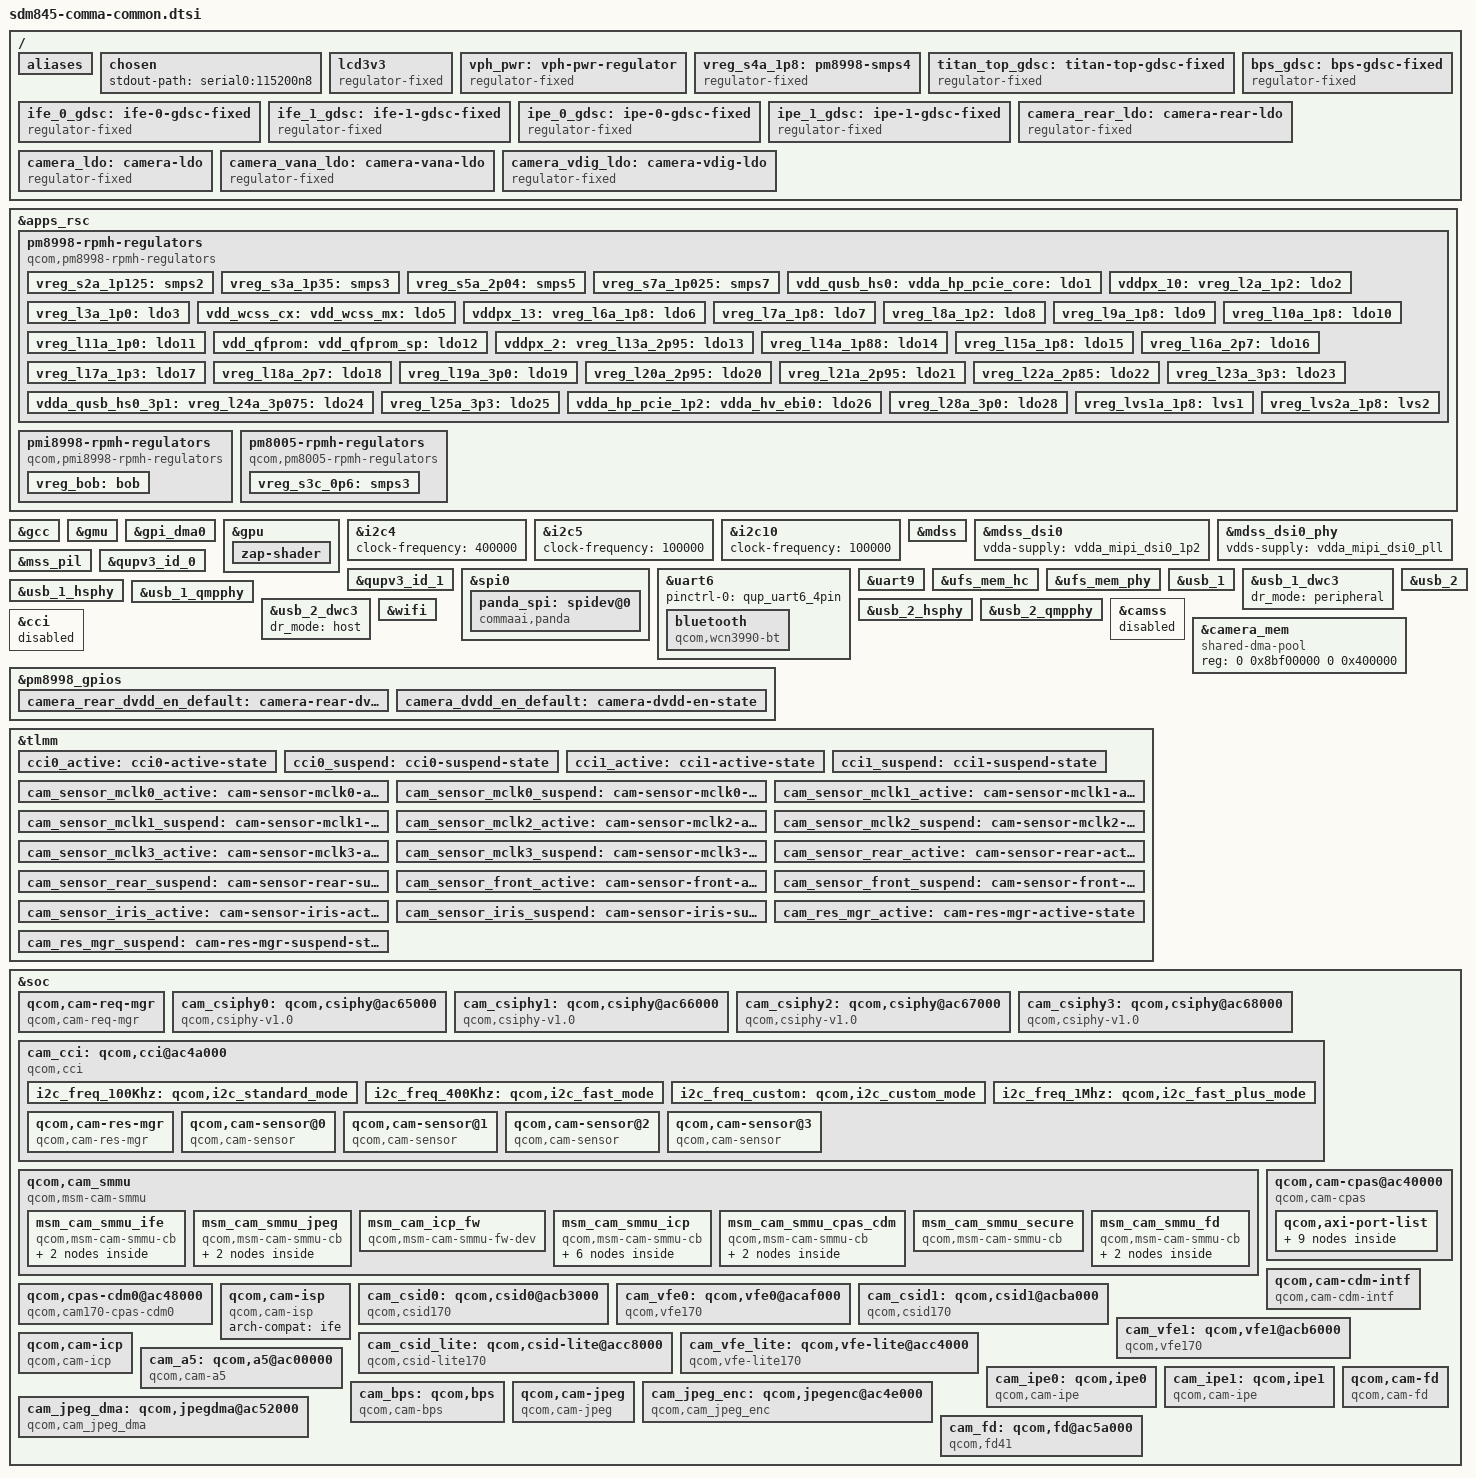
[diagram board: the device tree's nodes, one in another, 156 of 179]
/dts-v1/;

#include <dt-bindings/regulator/qcom,rpmh-regulator.h>
#include <dt-bindings/pinctrl/qcom,pmic-gpio.h>
#include "sdm845.dtsi"
#include "pm8998.dtsi"
#include "pmi8998.dtsi"

/ {
	aliases {
		serial0 = &uart9;

		/*
		 * openpilot opens fixed i2c bus numbers: IMU on bus 1
		 * (sensord.py I2C_BUS_IMU=1), ina231 power monitor on bus 0,
		 * touch on bus 2. Linux derives the adapter number from these
		 * aliases (of_alias_get_id). Upstream sdm845.dtsi ships identity
		 * aliases (i2cN=&i2cN), so without this override the IMU node
		 * (i2c@890000 = i2c4) would be bus 4. Remap the three buses we
		 * use to the legacy numbers and park the displaced identity
		 * aliases on unused nodes so no two aliases target one node.
		 *
		 * Matches agnos legacy DTS: se10=/dev/i2c-0 (power),
		 * se4=IMU bus 1, se5=/dev/i2c-2 (touch).
		 */
		i2c0 = &i2c10;	/* i2c@a88000  legacy /dev/i2c-0 (no devices on mici) */
		i2c1 = &i2c4;	/* i2c@890000  IMU            */
		i2c2 = &i2c5;	/* i2c@894000  touch          */
		i2c4 = &i2c0;
		i2c5 = &i2c1;
		i2c10 = &i2c2;
	};

	chosen {
		stdout-path = "serial0:115200n8";
	};

	lcd3v3: lcd3v3 {
		compatible = "regulator-fixed";
		regulator-name = "lcd3v3";
		regulator-min-microvolt = <3300000>;
		regulator-max-microvolt = <3300000>;
		gpio = <&pm8998_gpios 13 0>;
		regulator-boot-on;
	};

	vph_pwr: vph-pwr-regulator {
		compatible = "regulator-fixed";
		regulator-name = "vph_pwr";
		regulator-min-microvolt = <3700000>;
		regulator-max-microvolt = <3700000>;
	};

	/*
	 * Apparently RPMh does not provide support for PM8998 S4 because it
	 * is always-on; model it as a fixed regulator.
	 */
	vreg_s4a_1p8: pm8998-smps4 {
		compatible = "regulator-fixed";
		regulator-name = "vreg_s4a_1p8";

		regulator-min-microvolt = <1800000>;
		regulator-max-microvolt = <1800000>;

		regulator-always-on;
		regulator-boot-on;

		vin-supply = <&vph_pwr>;
	};

	/*
	 * Camera GDSC stand-in regulators (Spectra port).
	 *
	 * The downstream Spectra camera driver (cam_soc_util.c) acquires its
	 * power domains via the *regulator* framework: regulator_get(dev,
	 * "camss-vdd"/"gdscr"/"ife0"/...) — it has no genpd/pm_runtime path.
	 * On the legacy 4.9 tree titan_top_gdsc / ife_*_gdsc / ipe_*_gdsc /
	 * bps_gdsc were "qcom,gdsc" regulators poking individual registers in
	 * the camcc block. In mainline 6.18 those same registers belong to the
	 * &clock_camcc clock-controller, which exposes them as genpd
	 * power-domains (#power-domain-cells=1, TITAN_TOP_GDSC etc.) — there is
	 * no standalone gdsc regulator to point at. So provide always-on fixed
	 * regulators with the legacy labels to satisfy the driver's
	 * regulator_get() calls; the genuine HW power-gating is handled by the
	 * camcc genpd (the cam-cpas node additionally attaches TITAN_TOP_GDSC
	 * as a power-domain so the Titan top rail is actually enabled — see
	 * &soc cam-cpas below). always-on/boot-on keeps the bring-up faithful.
	 */
	titan_top_gdsc: titan-top-gdsc-fixed {
		compatible = "regulator-fixed";
		regulator-name = "titan_top_gdsc";
		regulator-always-on;
		regulator-boot-on;
	};

	ife_0_gdsc: ife-0-gdsc-fixed {
		compatible = "regulator-fixed";
		regulator-name = "ife_0_gdsc";
		regulator-always-on;
		regulator-boot-on;
	};

	ife_1_gdsc: ife-1-gdsc-fixed {
		compatible = "regulator-fixed";
		regulator-name = "ife_1_gdsc";
		regulator-always-on;
		regulator-boot-on;
	};

	ipe_0_gdsc: ipe-0-gdsc-fixed {
		compatible = "regulator-fixed";
		regulator-name = "ipe_0_gdsc";
		regulator-always-on;
		regulator-boot-on;
	};

	ipe_1_gdsc: ipe-1-gdsc-fixed {
		compatible = "regulator-fixed";
		regulator-name = "ipe_1_gdsc";
		regulator-always-on;
		regulator-boot-on;
	};

	bps_gdsc: bps-gdsc-fixed {
		compatible = "regulator-fixed";
		regulator-name = "bps_gdsc";
		regulator-always-on;
		regulator-boot-on;
	};

	/*
	 * Per-sensor digital/analog LDOs (Spectra port). Legacy
	 * sdm845-camera-sensor-mtp.dtsi modeled these as GPIO-gated
	 * regulator-fixed nodes (camera_rear_ldo / camera_ldo on pm8998 GPIOs
	 * 12/9; camera_vana_ldo / camera_vdig_ldo as always-on fixed). Kept
	 * identical here so the cam-sensor nodes' cam_vdig/cam_vana supplies
	 * resolve to the same rails as the working legacy DTS.
	 */
	/*
	 * cam_vdig (1.05 V) stand-ins, GPIO-enabled via pm8998 gpio12 (sensors
	 * 0-2) / gpio9 (sensor 3). Follows the mainline db845c cam0_dvdd_1v2
	 * pattern exactly: regulator-fixed + enable-active-high gpiod + a
	 * pinctrl-0 that muxes the pm8998 pin to a push-pull, high-strength
	 * output (the SPMI GPIO output buffer is open-drain/weak by default, so
	 * without drive-push-pull a gpiod output-high reads back low / high-Z and
	 * never sources the LDO enable — that was the CCI chip-id NACK). The
	 * device core applies pinctrl-0 (PINCTRL_STATE_DEFAULT) before probe, so
	 * the function/drive config lands before fixed.c requests the gpiod.
	 */
	camera_rear_ldo: camera-rear-ldo {
		compatible = "regulator-fixed";
		regulator-name = "camera_rear_ldo";
		regulator-min-microvolt = <1050000>;
		regulator-max-microvolt = <1050000>;
		gpio = <&pm8998_gpios 12 GPIO_ACTIVE_HIGH>;
		enable-active-high;
		pinctrl-names = "default";
		pinctrl-0 = <&camera_rear_dvdd_en_default>;
		regulator-always-on;
		regulator-boot-on;
	};

	camera_ldo: camera-ldo {
		compatible = "regulator-fixed";
		regulator-name = "camera_ldo";
		regulator-min-microvolt = <1050000>;
		regulator-max-microvolt = <1050000>;
		gpio = <&pm8998_gpios 9 GPIO_ACTIVE_HIGH>;
		enable-active-high;
		pinctrl-names = "default";
		pinctrl-0 = <&camera_dvdd_en_default>;
		regulator-always-on;
		regulator-boot-on;
	};

	camera_vana_ldo: camera-vana-ldo {
		compatible = "regulator-fixed";
		regulator-name = "camera_vana_ldo";
		regulator-min-microvolt = <2850000>;
		regulator-max-microvolt = <2850000>;
		regulator-enable-ramp-delay = <233>;
		enable-active-high;
	};

	camera_vdig_ldo: camera-vdig-ldo {
		compatible = "regulator-fixed";
		regulator-name = "camera_vdig_ldo";
		regulator-min-microvolt = <1050000>;
		regulator-max-microvolt = <1050000>;
		regulator-enable-ramp-delay = <233>;
		enable-active-high;
	};
};

&apps_rsc {
	pm8998-rpmh-regulators {
		compatible = "qcom,pm8998-rpmh-regulators";
		qcom,pmic-id = "a";

		vdd-s1-supply = <&vph_pwr>;
		vdd-s2-supply = <&vph_pwr>;
		vdd-s3-supply = <&vph_pwr>;
		vdd-s4-supply = <&vph_pwr>;
		vdd-s5-supply = <&vph_pwr>;
		vdd-s6-supply = <&vph_pwr>;
		vdd-s7-supply = <&vph_pwr>;
		vdd-s8-supply = <&vph_pwr>;
		vdd-s9-supply = <&vph_pwr>;
		vdd-s10-supply = <&vph_pwr>;
		vdd-s11-supply = <&vph_pwr>;
		vdd-s12-supply = <&vph_pwr>;
		vdd-s13-supply = <&vph_pwr>;
		vdd-l1-l27-supply = <&vreg_s7a_1p025>;
		vdd-l2-l8-l17-supply = <&vreg_s3a_1p35>;
		vdd-l3-l11-supply = <&vreg_s7a_1p025>;
		vdd-l4-l5-supply = <&vreg_s7a_1p025>;
		vdd-l6-supply = <&vph_pwr>;
		vdd-l7-l12-l14-l15-supply = <&vreg_s5a_2p04>;
		vdd-l9-supply = <&vreg_bob>;
		vdd-l10-l23-l25-supply = <&vreg_bob>;
		vdd-l13-l19-l21-supply = <&vreg_bob>;
		vdd-l16-l28-supply = <&vreg_bob>;
		vdd-l18-l22-supply = <&vreg_bob>;
		vdd-l20-l24-supply = <&vreg_bob>;
		vdd-l26-supply = <&vreg_s3a_1p35>;
		vin-lvs-1-2-supply = <&vreg_s4a_1p8>;

		vreg_s2a_1p125: smps2 {
			regulator-min-microvolt = <1100000>;
			regulator-max-microvolt = <1100000>;
		};

		vreg_s3a_1p35: smps3 {
			regulator-min-microvolt = <1352000>;
			regulator-max-microvolt = <1352000>;
		};

		vreg_s5a_2p04: smps5 {
			regulator-min-microvolt = <1904000>;
			regulator-max-microvolt = <2040000>;
		};

		vreg_s7a_1p025: smps7 {
			regulator-min-microvolt = <900000>;
			regulator-max-microvolt = <1028000>;
		};

		vdd_qusb_hs0:
		vdda_hp_pcie_core:
		vdda_mipi_csi0_0p9:
		vdda_mipi_csi1_0p9:
		vdda_mipi_csi2_0p9:
		vdda_mipi_dsi0_pll:
		vdda_mipi_dsi1_pll:
		vdda_qlink_lv:
		vdda_qlink_lv_ck:
		vdda_qrefs_0p875:
		vdda_pcie_core:
		vdda_pll_cc_ebi01:
		vdda_pll_cc_ebi23:
		vdda_sp_sensor:
		vdda_ufs1_core:
		vdda_ufs2_core:
		vdda_usb1_ss_core:
		vdda_usb2_ss_core:
		vreg_l1a_0p875: ldo1 {
			regulator-min-microvolt = <880000>;
			regulator-max-microvolt = <880000>;
			regulator-initial-mode = <RPMH_REGULATOR_MODE_HPM>;
		};

		vddpx_10:
		vreg_l2a_1p2: ldo2 {
			regulator-min-microvolt = <1200000>;
			regulator-max-microvolt = <1200000>;
			regulator-initial-mode = <RPMH_REGULATOR_MODE_HPM>;
			regulator-always-on;
		};

		vreg_l3a_1p0: ldo3 {
			regulator-min-microvolt = <1000000>;
			regulator-max-microvolt = <1000000>;
			regulator-initial-mode = <RPMH_REGULATOR_MODE_HPM>;
		};

		vdd_wcss_cx:
		vdd_wcss_mx:
		vdda_wcss_pll:
		vreg_l5a_0p8: ldo5 {
			regulator-min-microvolt = <800000>;
			regulator-max-microvolt = <800000>;
			regulator-initial-mode = <RPMH_REGULATOR_MODE_HPM>;
		};

		vddpx_13:
		vreg_l6a_1p8: ldo6 {
			regulator-min-microvolt = <1856000>;
			regulator-max-microvolt = <1856000>;
			regulator-initial-mode = <RPMH_REGULATOR_MODE_HPM>;
		};

		vreg_l7a_1p8: ldo7 {
			regulator-min-microvolt = <1800000>;
			regulator-max-microvolt = <1800000>;
			regulator-initial-mode = <RPMH_REGULATOR_MODE_HPM>;
		};

		vreg_l8a_1p2: ldo8 {
			regulator-min-microvolt = <1200000>;
			regulator-max-microvolt = <1248000>;
			regulator-initial-mode = <RPMH_REGULATOR_MODE_HPM>;
		};

		vreg_l9a_1p8: ldo9 {
			regulator-min-microvolt = <1704000>;
			regulator-max-microvolt = <2928000>;
			regulator-initial-mode = <RPMH_REGULATOR_MODE_HPM>;
		};

		vreg_l10a_1p8: ldo10 {
			regulator-min-microvolt = <1704000>;
			regulator-max-microvolt = <2928000>;
			regulator-initial-mode = <RPMH_REGULATOR_MODE_HPM>;
		};

		vreg_l11a_1p0: ldo11 {
			regulator-min-microvolt = <1000000>;
			regulator-max-microvolt = <1048000>;
			regulator-initial-mode = <RPMH_REGULATOR_MODE_HPM>;
		};

		vdd_qfprom:
		vdd_qfprom_sp:
		vdda_apc1_cs_1p8:
		vdda_gfx_cs_1p8:
		vdda_qrefs_1p8:
		vdda_qusb_hs0_1p8:
		vddpx_11:
		vreg_l12a_1p8: ldo12 {
			regulator-min-microvolt = <1800000>;
			regulator-max-microvolt = <1800000>;
			regulator-initial-mode = <RPMH_REGULATOR_MODE_HPM>;
		};

		vddpx_2:
		vreg_l13a_2p95: ldo13 {
			regulator-min-microvolt = <1800000>;
			regulator-max-microvolt = <2960000>;
			regulator-initial-mode = <RPMH_REGULATOR_MODE_HPM>;
		};

		vreg_l14a_1p88: ldo14 {
			regulator-min-microvolt = <1800000>;
			regulator-max-microvolt = <1800000>;
			regulator-initial-mode = <RPMH_REGULATOR_MODE_HPM>;
		};

		vreg_l15a_1p8: ldo15 {
			regulator-min-microvolt = <1800000>;
			regulator-max-microvolt = <1800000>;
			regulator-initial-mode = <RPMH_REGULATOR_MODE_HPM>;
		};

		vreg_l16a_2p7: ldo16 {
			regulator-min-microvolt = <2704000>;
			regulator-max-microvolt = <2704000>;
			regulator-initial-mode = <RPMH_REGULATOR_MODE_HPM>;
		};

		vreg_l17a_1p3: ldo17 {
			regulator-min-microvolt = <1304000>;
			regulator-max-microvolt = <1304000>;
			regulator-initial-mode = <RPMH_REGULATOR_MODE_HPM>;
		};

		vreg_l18a_2p7: ldo18 {
			regulator-min-microvolt = <2704000>;
			regulator-max-microvolt = <2960000>;
			regulator-initial-mode = <RPMH_REGULATOR_MODE_HPM>;
		};

		vreg_l19a_3p0: ldo19 {
			regulator-min-microvolt = <2856000>;
			regulator-max-microvolt = <3104000>;
			regulator-initial-mode = <RPMH_REGULATOR_MODE_HPM>;
		};

		vreg_l20a_2p95: ldo20 {
			regulator-min-microvolt = <2704000>;
			regulator-max-microvolt = <2960000>;
			regulator-initial-mode = <RPMH_REGULATOR_MODE_HPM>;
		};

		vreg_l21a_2p95: ldo21 {
			regulator-min-microvolt = <2704000>;
			regulator-max-microvolt = <2960000>;
			regulator-initial-mode = <RPMH_REGULATOR_MODE_HPM>;
		};

		vreg_l22a_2p85: ldo22 {
			regulator-min-microvolt = <2864000>;
			regulator-max-microvolt = <3312000>;
			regulator-initial-mode = <RPMH_REGULATOR_MODE_HPM>;
		};

		vreg_l23a_3p3: ldo23 {
			regulator-min-microvolt = <3000000>;
			regulator-max-microvolt = <3312000>;
			regulator-initial-mode = <RPMH_REGULATOR_MODE_HPM>;
		};

		vdda_qusb_hs0_3p1:
		vreg_l24a_3p075: ldo24 {
			regulator-min-microvolt = <3088000>;
			regulator-max-microvolt = <3088000>;
			regulator-initial-mode = <RPMH_REGULATOR_MODE_HPM>;
		};

		vreg_l25a_3p3: ldo25 {
			regulator-min-microvolt = <3300000>;
			regulator-max-microvolt = <3312000>;
			regulator-initial-mode = <RPMH_REGULATOR_MODE_HPM>;
		};

		vdda_hp_pcie_1p2:
		vdda_hv_ebi0:
		vdda_hv_ebi1:
		vdda_hv_ebi2:
		vdda_hv_ebi3:
		vdda_mipi_csi_1p25:
		vdda_mipi_dsi0_1p2:
		vdda_mipi_dsi1_1p2:
		vdda_pcie_1p2:
		vdda_ufs1_1p2:
		vdda_ufs2_1p2:
		vdda_usb1_ss_1p2:
		vdda_usb2_ss_1p2:
		vreg_l26a_1p2: ldo26 {
			regulator-min-microvolt = <1200000>;
			regulator-max-microvolt = <1200000>;
			regulator-initial-mode = <RPMH_REGULATOR_MODE_HPM>;
		};

		vreg_l28a_3p0: ldo28 {
			regulator-min-microvolt = <2856000>;
			regulator-max-microvolt = <3008000>;
			regulator-initial-mode = <RPMH_REGULATOR_MODE_HPM>;
		};

		vreg_lvs1a_1p8: lvs1 {
			regulator-min-microvolt = <1800000>;
			regulator-max-microvolt = <1800000>;
		};

		vreg_lvs2a_1p8: lvs2 {
			regulator-min-microvolt = <1800000>;
			regulator-max-microvolt = <1800000>;
		};
	};

	pmi8998-rpmh-regulators {
		compatible = "qcom,pmi8998-rpmh-regulators";
		qcom,pmic-id = "b";

		vdd-bob-supply = <&vph_pwr>;

		vreg_bob: bob {
			regulator-min-microvolt = <3312000>;
			regulator-max-microvolt = <3600000>;
			regulator-initial-mode = <RPMH_REGULATOR_MODE_AUTO>;
			regulator-allow-bypass;
		};
	};

	pm8005-rpmh-regulators {
		compatible = "qcom,pm8005-rpmh-regulators";
		qcom,pmic-id = "c";

		vdd-s1-supply = <&vph_pwr>;
		vdd-s2-supply = <&vph_pwr>;
		vdd-s3-supply = <&vph_pwr>;
		vdd-s4-supply = <&vph_pwr>;

		vreg_s3c_0p6: smps3 {
			regulator-min-microvolt = <600000>;
			regulator-max-microvolt = <600000>;
		};
	};
};

&gcc {
	protected-clocks = <GCC_QSPI_CORE_CLK>,
			   <GCC_QSPI_CORE_CLK_SRC>,
			   <GCC_QSPI_CNOC_PERIPH_AHB_CLK>,
			   <GCC_LPASS_Q6_AXI_CLK>,
			   <GCC_LPASS_SWAY_CLK>;
};

&gmu {
	status = "okay";
};

&gpi_dma0 {
	status = "okay";
};

&gpu {
	status = "okay";

	zap-shader {
		memory-region = <&gpu_mem>;
		firmware-name = "qcom/sdm845/a630_zap.mbn";
	};
};

&i2c4 {
	status = "okay";
	clock-frequency = <400000>;
};

&i2c5 {
	status = "okay";
	clock-frequency = <100000>;
};

/*
 * Legacy /dev/i2c-0 (SE10, a88000) -> aliased to bus 0 above. On the comma
 * four this bus carries no devices openpilot uses: there is NO ina231 (legacy
 * comma_mici.dts /delete-node's it as "not populated on mici" — confirmed on
 * device: probe of 0x40 returns -ENXIO, bus scan empty). openpilot reads power
 * from the PMIC bms power_supply, not this bus. Kept enabled only to preserve
 * bus-0 numbering parity with legacy.
 */
&i2c10 {
	status = "okay";
	clock-frequency = <100000>;
};

&mdss {
	status = "okay";
};

&mdss_dsi0 {
	status = "okay";
	vdda-supply = <&vdda_mipi_dsi0_1p2>;
};

&mdss_dsi0_phy {
	status = "okay";
	vdds-supply = <&vdda_mipi_dsi0_pll>;
};

&mss_pil {
	status = "okay";
	firmware-name = "qcom/sdm845/mba.mbn", "qcom/sdm845/modem_nm.mbn";
};

&qupv3_id_0 {
	status = "okay";
};

&qupv3_id_1 {
	status = "okay";
};

&spi0 {
	status = "okay";

	panda_spi: spidev@0 {
		compatible = "commaai,panda";
		spi-max-frequency = <50000000>;
		reg = <0>;
	};
};

&uart6 {
	status = "okay";
	pinctrl-0 = <&qup_uart6_4pin>;

	bluetooth {
		compatible = "qcom,wcn3990-bt";
		vddio-supply = <&vreg_s4a_1p8>;
		vddxo-supply = <&vreg_l7a_1p8>;
		vddrf-supply = <&vreg_l17a_1p3>;
		vddch0-supply = <&vreg_l25a_3p3>;
		max-speed = <3200000>;
	};
};

&uart9 {
	status = "okay";
};

&ufs_mem_hc {
	status = "okay";

	reset-gpios = <&tlmm 150 GPIO_ACTIVE_LOW>;

	vcc-supply = <&vreg_l20a_2p95>;
	vcc-max-microamp = <600000>;
};

&ufs_mem_phy {
	status = "okay";

	vdda-phy-supply = <&vdda_ufs1_core>;
	vdda-pll-supply = <&vdda_ufs1_1p2>;
	vdda-phy-max-microamp = <62900>;
	vdda-pll-max-microamp = <18300>;
};

&usb_1 {
	status = "okay";
};

&usb_1_dwc3 {
	dr_mode = "peripheral";
};

&usb_1_hsphy {
	status = "okay";

	vdd-supply = <&vdd_qusb_hs0>;
	vdda-phy-dpdm-supply = <&vdda_qusb_hs0_3p1>;
	vdda-pll-supply = <&vdda_qusb_hs0_1p8>;
};

&usb_1_qmpphy {
	status = "okay";

	vdda-phy-supply = <&vdda_usb1_ss_1p2>;
	vdda-pll-supply = <&vdda_usb1_ss_core>;
};

&usb_2 {
	status = "okay";
};

&usb_2_dwc3 {
	dr_mode = "host";
};

&usb_2_hsphy {
	status = "okay";

	vdd-supply = <&vdd_qusb_hs0>;
	vdda-pll-supply = <&vdda_qusb_hs0_1p8>;
	vdda-phy-dpdm-supply = <&vdda_qusb_hs0_3p1>;
};

&usb_2_qmpphy {
	status = "okay";

	vdda-phy-supply = <&vdda_usb2_ss_1p2>;
	vdda-pll-supply = <&vdda_usb2_ss_core>;
};

&vreg_lvs1a_1p8 {
	regulator-always-on;
};

&wifi {
	status = "okay";

	vdd-0.8-cx-mx-supply = <&vreg_l5a_0p8>;
	vdd-1.3-rfa-supply = <&vreg_l17a_1p3>;
	vdd-1.8-xo-supply = <&vreg_l7a_1p8>;
	vdd-3.3-ch0-supply = <&vreg_l25a_3p3>;
	vdd-3.3-ch1-supply = <&vreg_l23a_3p3>;

	qcom,snoc-host-cap-skip-quirk;
};

/* ========================================================================
 * Camera subsystem (Spectra port — DESIGN.md / TASKS.md Phase 3.1)
 *
 * The mainline qcom-camss + cci nodes claim the SAME register regions as
 * the downstream Spectra cam-isp/CSID/CSIPHY/VFE and CCI nodes we add
 * below (camerad talks the Spectra ABI, not qcom-camss). Disable the
 * upstream nodes so only the Spectra nodes own those regions.
 *
 * Reg-overlap proof (mainline sdm845.dtsi camss@acb3000 reg list vs the
 * Spectra nodes below):
 *   upstream camss csid0   0xacb3000  == Spectra cam_csid0@acb3000
 *   upstream camss csid1   0xacba000  == Spectra cam_csid1@acba000
 *   upstream camss csid2   0xacc8000  == Spectra cam_csid_lite@acc8000
 *   upstream camss csiphy0 0xac65000  == Spectra cam_csiphy0@ac65000
 *   upstream camss csiphy1 0xac66000  == Spectra cam_csiphy1@ac66000
 *   upstream camss csiphy2 0xac67000  == Spectra cam_csiphy2@ac67000
 *   upstream camss csiphy3 0xac68000  == Spectra cam_csiphy3@ac68000
 *   upstream camss vfe0    0xacaf000  == Spectra cam_vfe0@acaf000
 *   upstream camss vfe1    0xacb6000  == Spectra cam_vfe1@acb6000
 *   upstream camss vfelite 0xacc4000  == Spectra cam_vfe_lite@acc4000
 *   upstream cci@ac4a000   0xac4a000  == Spectra cam_cci@ac4a000
 * (mainline has no separate ispif/cdm/cpas/icp/jpeg/fd nodes — they live
 * only inside camss@acb3000, so disabling camss clears them all.)
 * ======================================================================== */
&camss {
	status = "disabled";
};

&cci {
	status = "disabled";
};

/*
 * Camera pinctrl states (mainline flat -state binding, qcom,sdm845-pinctrl).
 * Legacy sdm845-pinctrl.dtsi defined these with nested mux{}/config{}; the
 * 6.18 driver wants properties directly under the state node (cf. the stock
 * cci0_default state). cam_mclk / cci_i2c / gpio functions all exist for
 * these pins (pinctrl-sdm845.c PINGROUP table). The Spectra cam_soc_util
 * acquires them via devm_pinctrl_get + pinctrl_lookup_state by name.
 */
/*
 * pm8998 GPIO pinconf for the camera DVDD-enable lines (gpio12 = cam_vdig
 * sensors 0-2, gpio9 = sensor 3). drive-push-pull + high strength is the key:
 * the SPMI GPIO output buffer is weak/open-drain by default, so a gpiod
 * output-high would read back low and never source the LDO enable. function
 * "normal" selects GPIO mode. The value is owned by the regulator's gpiod
 * (enable-active-high), so no output-low/high here. Mirrors db845c
 * cam0_dvdd_1v2_en_default and the legacy camera_*_dvdd_en_default states.
 */
&pm8998_gpios {
	/*
	 * Apply the camera DVDD-enable pinconf on the spmi-gpio CONTROLLER's own
	 * default pinctrl (the platform device probes, so the core applies it).
	 * The regulator-fixed's pinctrl-0 does NOT apply on this kernel (no
	 * pinctrl handle bound), and a gpio-hog can only set the value, not the
	 * pinconf — and the SPMI output buffer defaults to open-drain, so
	 * output-high without drive-push-pull floats and reads back low. So set
	 * the full pinconf here: function=normal + push-pull + high strength +
	 * output-high (PIN_CONFIG_LEVEL → output_enabled + out_value=1, mode =
	 * DIGITAL_OUTPUT in pmic_gpio_config_set). This drives cam_vdig on
	 * unconditionally whenever the board is powered (legacy keeps it on
	 * across camera use); the regulators below are plain always-on stand-ins.
	 */
	camera_rear_dvdd_en_default: camera-rear-dvdd-en-state {
		pins = "gpio12";
		function = "normal";
		bias-disable;
		drive-push-pull;
		qcom,drive-strength = <PMIC_GPIO_STRENGTH_HIGH>;
		output-high;
	};

	camera_dvdd_en_default: camera-dvdd-en-state {
		pins = "gpio9";
		function = "normal";
		bias-disable;
		drive-push-pull;
		qcom,drive-strength = <PMIC_GPIO_STRENGTH_HIGH>;
		output-high;
	};
};

&tlmm {
	cci0_active: cci0-active-state {
		pins = "gpio17", "gpio18";
		function = "cci_i2c";
		bias-pull-up;
		drive-strength = <2>;
	};

	cci0_suspend: cci0-suspend-state {
		pins = "gpio17", "gpio18";
		function = "cci_i2c";
		bias-pull-down;
		drive-strength = <2>;
	};

	cci1_active: cci1-active-state {
		pins = "gpio19", "gpio20";
		function = "cci_i2c";
		bias-pull-up;
		drive-strength = <2>;
	};

	cci1_suspend: cci1-suspend-state {
		pins = "gpio19", "gpio20";
		function = "cci_i2c";
		bias-pull-down;
		drive-strength = <2>;
	};

	cam_sensor_mclk0_active: cam-sensor-mclk0-active-state {
		pins = "gpio13";
		function = "cam_mclk";
		bias-disable;
		drive-strength = <8>;
	};

	cam_sensor_mclk0_suspend: cam-sensor-mclk0-suspend-state {
		pins = "gpio13";
		function = "cam_mclk";
		bias-pull-down;
		drive-strength = <8>;
	};

	cam_sensor_mclk1_active: cam-sensor-mclk1-active-state {
		pins = "gpio14";
		function = "cam_mclk";
		bias-disable;
		drive-strength = <8>;
	};

	cam_sensor_mclk1_suspend: cam-sensor-mclk1-suspend-state {
		pins = "gpio14";
		function = "cam_mclk";
		bias-pull-down;
		drive-strength = <8>;
	};

	cam_sensor_mclk2_active: cam-sensor-mclk2-active-state {
		pins = "gpio15";
		function = "cam_mclk";
		bias-disable;
		drive-strength = <8>;
	};

	cam_sensor_mclk2_suspend: cam-sensor-mclk2-suspend-state {
		pins = "gpio15";
		function = "cam_mclk";
		bias-pull-down;
		drive-strength = <8>;
	};

	cam_sensor_mclk3_active: cam-sensor-mclk3-active-state {
		pins = "gpio16";
		function = "cam_mclk";
		bias-disable;
		drive-strength = <2>;
	};

	cam_sensor_mclk3_suspend: cam-sensor-mclk3-suspend-state {
		pins = "gpio16";
		function = "cam_mclk";
		bias-pull-down;
		drive-strength = <2>;
	};

	cam_sensor_rear_active: cam-sensor-rear-active-state {
		pins = "gpio9";
		function = "gpio";
		bias-disable;
		drive-strength = <2>;
	};

	cam_sensor_rear_suspend: cam-sensor-rear-suspend-state {
		pins = "gpio9";
		function = "gpio";
		bias-pull-down;
		drive-strength = <2>;
		output-low;
	};

	cam_sensor_front_active: cam-sensor-front-active-state {
		pins = "gpio28";
		function = "gpio";
		bias-disable;
		drive-strength = <2>;
	};

	cam_sensor_front_suspend: cam-sensor-front-suspend-state {
		pins = "gpio28";
		function = "gpio";
		bias-pull-down;
		drive-strength = <2>;
		output-low;
	};

	cam_sensor_iris_active: cam-sensor-iris-active-state {
		pins = "gpio21";
		function = "gpio";
		bias-disable;
		drive-strength = <2>;
	};

	cam_sensor_iris_suspend: cam-sensor-iris-suspend-state {
		pins = "gpio21";
		function = "gpio";
		bias-pull-down;
		drive-strength = <2>;
		output-low;
	};

	cam_res_mgr_active: cam-res-mgr-active-state {
		pins = "gpio8";
		function = "gpio";
		bias-disable;
		drive-strength = <2>;
	};

	cam_res_mgr_suspend: cam-res-mgr-suspend-state {
		pins = "gpio8";
		function = "gpio";
		bias-disable;
		drive-strength = <2>;
		output-low;
	};
};

/* ========================================================================
 * ICP firmware carveout (camera_mem) — make it a per-device coherent pool.
 *
 * cam_smmu_alloc_firmware() does dma_alloc_coherent(fw_dev) then
 * iommu_map(icp_domain, IOVA 0x0, dma_handle, len) and a5_core memcpy_toio()s
 * the CAMERA_ICP.elf segments into the returned kva; the A5 then fetches the FW
 * from IOVA 0x0 through its own SMMU context bank. For that to work the kva the
 * host writes and the physical pages the A5 reads must be the SAME memory, with
 * a write-combine (uncached) attribute so memcpy_toio() is immediately visible
 * to the A5 (no dirty-cache races) and the dma_handle is PA-identity so the
 * iommu_map() points at the right pages.
 *
 * Legacy 4.9 achieved this with `compatible = "removed-dma-pool"` on
 * pil_camera_mem. Mainline 6.18 has NO removed-dma-pool driver; the equivalent
 * is `shared-dma-pool` + `no-map`, which kernel/dma/coherent.c handles as a
 * per-device coherent pool via memremap(..., MEMREMAP_WC) with PA-identity
 * handles — exactly the legacy semantics. Upstream sdm845.dtsi declares
 * camera_mem as bare `no-map` (removed from the linear map, NOT a coherent
 * pool), so without this override dma_alloc_coherent(fw_dev) falls back to the
 * default allocator and the A5 boots stale/wrong FW -> watchdog. Add the
 * shared-dma-pool compatible so fw_dev binds this region as its coherent pool.
 */
&camera_mem {
	compatible = "shared-dma-pool";
	/* no-map already set upstream; required by rmem_dma_setup */
	/*
	 * Resize 5 MiB -> 4 MiB (power of two). The per-device coherent pool
	 * allocator (kernel/dma/coherent.c __dma_alloc_from_coherent) rounds the
	 * request up to 2^get_order(size) PAGES via bitmap_find_free_region(), so a
	 * 5 MiB (1280-page) request needs order-11 = 2048 pages = 8 MiB and FAILS
	 * against a 5 MiB pool ("FW memory alloc failed"). The legacy 4.9
	 * removed-dma-pool did contiguous (non-power-of-two) allocation, so 5 MiB
	 * worked there. 4 MiB is exactly order-10 (1024 pages) so the whole pool is
	 * one aligned power-of-two block: dma_alloc_coherent() succeeds and returns
	 * the pool base 0x8bf00000 (PA-identity). 4 MiB comfortably exceeds the
	 * ~1.1 MiB CAMERA_ICP.elf. The firmware IOVA region (msm_cam_smmu_icp,
	 * iova-mem-region-firmware) is shrunk to 0x400000 to match this length so
	 * the iommu_map(IOVA 0x0, dma_handle, len) covers exactly the backed pages.
	 * Base stays 0x8bf00000; new end 0x8c300000 still clears ipa_fw@0x8c400000.
	 */
	reg = <0 0x8bf00000 0 0x400000>;
};

/* ========================================================================
 * Spectra camera HW blocks (ported from legacy sdm845-camera.dtsi).
 *
 * Transforms applied vs legacy 4.9 DTS:
 *  - &clock_gcc -> &gcc                (mainline GCC label)
 *  - &clock_camcc kept                 (mainline camcc label is clock_camcc;
 *                                       Spectra acquires clks via clk_get by
 *                                       clock-names + clk_set_rate, so the
 *                                       CCF camcc named CAM_CC_* phandles are
 *                                       drop-in — no syscon needed)
 *  - interrupts <0 N 0> -> <GIC_SPI N IRQ_TYPE_EDGE_RISING> (matches the
 *                                       mainline camss interrupt encoding)
 *  - &titan_top_gdsc/&ife_*_gdsc/&ipe_*_gdsc/&bps_gdsc now resolve to the
 *    always-on fixed-regulator stand-ins added at top of this file (the real
 *    gdsc regs are owned by &clock_camcc genpd in mainline; cam-cpas also
 *    attaches TITAN_TOP_GDSC as a power-domain to actually gate the rail)
 *  - mipi-csi-vdd-supply &pm8998_l1 -> &vreg_l1a_0p875
 *  - memory-region &pil_camera_mem -> &camera_mem (mainline 5MB no-map region)
 *  - qcom,msm-bus,* AXI vectors dropped (2.C ported msm-bus -> interconnect;
 *    icc votes degrade to safe no-op until paths are wired — see notes). The
 *    qcom,axi-port-list structure is KEPT verbatim: cam_cpas_hw.c requires it
 *    for probe (of_find_node_by_name "qcom,axi-port-list" + per-port mnoc/
 *    camnoc children, else -EINVAL).
 * ======================================================================== */
&soc {
	qcom,cam-req-mgr {
		compatible = "qcom,cam-req-mgr";
		status = "ok";
	};

	cam_csiphy0: qcom,csiphy@ac65000 {
		cell-index = <0>;
		compatible = "qcom,csiphy-v1.0", "qcom,csiphy";
		reg = <0 0x0ac65000 0 0x1000>;
		reg-names = "csiphy";
		reg-cam-base = <0x65000>;
		interrupts = <GIC_SPI 477 IRQ_TYPE_EDGE_RISING>;
		interrupt-names = "csiphy";
		gdscr-supply = <&titan_top_gdsc>;
		regulator-names = "gdscr";
		csi-vdd-voltage = <1200000>;
		mipi-csi-vdd-supply = <&vreg_l1a_0p875>;
		clocks = <&clock_camcc CAM_CC_CAMNOC_AXI_CLK>,
			<&clock_camcc CAM_CC_SOC_AHB_CLK>,
			<&clock_camcc CAM_CC_SLOW_AHB_CLK_SRC>,
			<&clock_camcc CAM_CC_CPAS_AHB_CLK>,
			<&clock_camcc CAM_CC_CPHY_RX_CLK_SRC>,
			<&clock_camcc CAM_CC_CSIPHY0_CLK>,
			<&clock_camcc CAM_CC_CSI0PHYTIMER_CLK_SRC>,
			<&clock_camcc CAM_CC_CSI0PHYTIMER_CLK>;
		clock-names = "camnoc_axi_clk",
			"soc_ahb_clk",
			"slow_ahb_src_clk",
			"cpas_ahb_clk",
			"cphy_rx_clk_src",
			"csiphy0_clk",
			"csi0phytimer_clk_src",
			"csi0phytimer_clk";
		src-clock-name = "csi0phytimer_clk_src";
		clock-cntl-level = "svs", "turbo";
		clock-rates =
			<0 0 0 0 320000000 0 269333333 0>,
			<0 0 0 0 384000000 0 269333333 0>;
		status = "ok";
	};

	cam_csiphy1: qcom,csiphy@ac66000 {
		cell-index = <1>;
		compatible = "qcom,csiphy-v1.0", "qcom,csiphy";
		reg = <0 0x0ac66000 0 0x1000>;
		reg-names = "csiphy";
		reg-cam-base = <0x66000>;
		interrupts = <GIC_SPI 478 IRQ_TYPE_EDGE_RISING>;
		interrupt-names = "csiphy";
		gdscr-supply = <&titan_top_gdsc>;
		regulator-names = "gdscr";
		csi-vdd-voltage = <1200000>;
		mipi-csi-vdd-supply = <&vreg_l1a_0p875>;
		clocks = <&clock_camcc CAM_CC_CAMNOC_AXI_CLK>,
			<&clock_camcc CAM_CC_SOC_AHB_CLK>,
			<&clock_camcc CAM_CC_SLOW_AHB_CLK_SRC>,
			<&clock_camcc CAM_CC_CPAS_AHB_CLK>,
			<&clock_camcc CAM_CC_CPHY_RX_CLK_SRC>,
			<&clock_camcc CAM_CC_CSIPHY1_CLK>,
			<&clock_camcc CAM_CC_CSI1PHYTIMER_CLK_SRC>,
			<&clock_camcc CAM_CC_CSI1PHYTIMER_CLK>;
		clock-names = "camnoc_axi_clk",
			"soc_ahb_clk",
			"slow_ahb_src_clk",
			"cpas_ahb_clk",
			"cphy_rx_clk_src",
			"csiphy1_clk",
			"csi1phytimer_clk_src",
			"csi1phytimer_clk";
		src-clock-name = "csi1phytimer_clk_src";
		clock-cntl-level = "svs", "turbo";
		clock-rates =
			<0 0 0 0 320000000 0 269333333 0>,
			<0 0 0 0 384000000 0 269333333 0>;
		status = "ok";
	};

	cam_csiphy2: qcom,csiphy@ac67000 {
		cell-index = <2>;
		compatible = "qcom,csiphy-v1.0", "qcom,csiphy";
		reg = <0 0x0ac67000 0 0x1000>;
		reg-names = "csiphy";
		reg-cam-base = <0x67000>;
		interrupts = <GIC_SPI 479 IRQ_TYPE_EDGE_RISING>;
		interrupt-names = "csiphy";
		gdscr-supply = <&titan_top_gdsc>;
		regulator-names = "gdscr";
		csi-vdd-voltage = <1200000>;
		mipi-csi-vdd-supply = <&vreg_l1a_0p875>;
		clocks = <&clock_camcc CAM_CC_CAMNOC_AXI_CLK>,
			<&clock_camcc CAM_CC_SOC_AHB_CLK>,
			<&clock_camcc CAM_CC_SLOW_AHB_CLK_SRC>,
			<&clock_camcc CAM_CC_CPAS_AHB_CLK>,
			<&clock_camcc CAM_CC_CPHY_RX_CLK_SRC>,
			<&clock_camcc CAM_CC_CSIPHY2_CLK>,
			<&clock_camcc CAM_CC_CSI2PHYTIMER_CLK_SRC>,
			<&clock_camcc CAM_CC_CSI2PHYTIMER_CLK>;
		clock-names = "camnoc_axi_clk",
			"soc_ahb_clk",
			"slow_ahb_src_clk",
			"cpas_ahb_clk",
			"cphy_rx_clk_src",
			"csiphy2_clk",
			"csi2phytimer_clk_src",
			"csi2phytimer_clk";
		src-clock-name = "csi2phytimer_clk_src";
		clock-cntl-level = "svs", "turbo";
		clock-rates =
			<0 0 0 0 320000000 0 269333333 0>,
			<0 0 0 0 384000000 0 269333333 0>;
		status = "ok";
	};

	cam_csiphy3: qcom,csiphy@ac68000 {
		cell-index = <3>;
		compatible = "qcom,csiphy-v1.0", "qcom,csiphy";
		reg = <0 0x0ac68000 0 0x1000>;
		reg-names = "csiphy";
		reg-cam-base = <0x68000>;
		interrupts = <GIC_SPI 448 IRQ_TYPE_EDGE_RISING>;
		interrupt-names = "csiphy";
		gdscr-supply = <&titan_top_gdsc>;
		regulator-names = "gdscr";
		csi-vdd-voltage = <1200000>;
		mipi-csi-vdd-supply = <&vreg_l1a_0p875>;
		clocks = <&clock_camcc CAM_CC_CAMNOC_AXI_CLK>,
			<&clock_camcc CAM_CC_SOC_AHB_CLK>,
			<&clock_camcc CAM_CC_SLOW_AHB_CLK_SRC>,
			<&clock_camcc CAM_CC_CPAS_AHB_CLK>,
			<&clock_camcc CAM_CC_CPHY_RX_CLK_SRC>,
			<&clock_camcc CAM_CC_CSIPHY3_CLK>,
			<&clock_camcc CAM_CC_CSI3PHYTIMER_CLK_SRC>,
			<&clock_camcc CAM_CC_CSI3PHYTIMER_CLK>;
		clock-names = "camnoc_axi_clk",
			"soc_ahb_clk",
			"slow_ahb_src_clk",
			"cpas_ahb_clk",
			"cphy_rx_clk_src",
			"csiphy3_clk",
			"csi3phytimer_clk_src",
			"csi3phytimer_clk";
		src-clock-name = "csi3phytimer_clk_src";
		clock-cntl-level = "svs", "turbo";
		clock-rates =
			<0 0 0 0 320000000 0 269333333 0>,
			<0 0 0 0 384000000 0 269333333 0>;
		status = "ok";
	};

	cam_cci: qcom,cci@ac4a000 {
		cell-index = <0>;
		compatible = "qcom,cci";
		#address-cells = <1>;
		#size-cells = <0>;
		reg = <0 0x0ac4a000 0 0x4000>;
		reg-names = "cci";
		reg-cam-base = <0x4a000>;
		interrupt-names = "cci";
		interrupts = <GIC_SPI 460 IRQ_TYPE_EDGE_RISING>;
		status = "ok";
		gdscr-supply = <&titan_top_gdsc>;
		regulator-names = "gdscr";
		clocks = <&clock_camcc CAM_CC_CAMNOC_AXI_CLK>,
			<&clock_camcc CAM_CC_SOC_AHB_CLK>,
			<&clock_camcc CAM_CC_SLOW_AHB_CLK_SRC>,
			<&clock_camcc CAM_CC_CPAS_AHB_CLK>,
			<&clock_camcc CAM_CC_CCI_CLK>,
			<&clock_camcc CAM_CC_CCI_CLK_SRC>;
		clock-names = "camnoc_axi_clk",
			"soc_ahb_clk",
			"slow_ahb_src_clk",
			"cpas_ahb_clk",
			"cci_clk",
			"cci_clk_src";
		src-clock-name = "cci_clk_src";
		clock-cntl-level = "lowsvs";
		clock-rates = <0 0 0 0 0 37500000>;
		pinctrl-names = "cam_default", "cam_suspend";
		pinctrl-0 = <&cci0_active &cci1_active>;
		pinctrl-1 = <&cci0_suspend &cci1_suspend>;
		gpios = <&tlmm 17 0>,
			<&tlmm 18 0>,
			<&tlmm 19 0>,
			<&tlmm 20 0>;
		gpio-req-tbl-num = <0 1 2 3>;
		gpio-req-tbl-flags = <1 1 1 1>;
		gpio-req-tbl-label = "CCI_I2C_DATA0",
					"CCI_I2C_CLK0",
					"CCI_I2C_DATA1",
					"CCI_I2C_CLK1";

		i2c_freq_100Khz: qcom,i2c_standard_mode {
			hw-thigh = <201>;
			hw-tlow = <174>;
			hw-tsu-sto = <204>;
			hw-tsu-sta = <231>;
			hw-thd-dat = <22>;
			hw-thd-sta = <162>;
			hw-tbuf = <227>;
			hw-scl-stretch-en = <0>;
			hw-trdhld = <6>;
			hw-tsp = <3>;
			cci-clk-src = <37500000>;
			status = "ok";
		};

		i2c_freq_400Khz: qcom,i2c_fast_mode {
			hw-thigh = <38>;
			hw-tlow = <56>;
			hw-tsu-sto = <40>;
			hw-tsu-sta = <40>;
			hw-thd-dat = <22>;
			hw-thd-sta = <35>;
			hw-tbuf = <62>;
			hw-scl-stretch-en = <0>;
			hw-trdhld = <6>;
			hw-tsp = <3>;
			cci-clk-src = <37500000>;
			status = "ok";
		};

		i2c_freq_custom: qcom,i2c_custom_mode {
			hw-thigh = <38>;
			hw-tlow = <56>;
			hw-tsu-sto = <40>;
			hw-tsu-sta = <40>;
			hw-thd-dat = <22>;
			hw-thd-sta = <35>;
			hw-tbuf = <62>;
			hw-scl-stretch-en = <1>;
			hw-trdhld = <6>;
			hw-tsp = <3>;
			cci-clk-src = <37500000>;
			status = "ok";
		};

		i2c_freq_1Mhz: qcom,i2c_fast_plus_mode {
			hw-thigh = <16>;
			hw-tlow = <22>;
			hw-tsu-sto = <17>;
			hw-tsu-sta = <18>;
			hw-thd-dat = <16>;
			hw-thd-sta = <15>;
			hw-tbuf = <24>;
			hw-scl-stretch-en = <0>;
			hw-trdhld = <3>;
			hw-tsp = <3>;
			cci-clk-src = <37500000>;
			status = "ok";
		};
	};

	qcom,cam_smmu {
		compatible = "qcom,msm-cam-smmu";
		status = "ok";

		msm_cam_smmu_ife {
			compatible = "qcom,msm-cam-smmu-cb";
			iommus = <&apps_smmu 0x808 0x0>,
				<&apps_smmu 0x810 0x8>,
				<&apps_smmu 0xc08 0x0>,
				<&apps_smmu 0xc10 0x8>;
			label = "ife";
			ife_iova_mem_map: iova-mem-map {
				iova-mem-region-io {
					iova-region-name = "io";
					iova-region-start = <0x7400000>;
					iova-region-len = <0xd8c00000>;
					iova-region-id = <0x3>;
					status = "ok";
				};
			};
		};

		msm_cam_smmu_jpeg {
			compatible = "qcom,msm-cam-smmu-cb";
			iommus = <&apps_smmu 0x1060 0x8>,
				<&apps_smmu 0x1068 0x8>;
			label = "jpeg";
			jpeg_iova_mem_map: iova-mem-map {
				iova-mem-region-io {
					iova-region-name = "io";
					iova-region-start = <0x7400000>;
					iova-region-len = <0xd8c00000>;
					iova-region-id = <0x3>;
					status = "ok";
				};
			};
		};

		msm_cam_icp_fw {
			compatible = "qcom,msm-cam-smmu-fw-dev";
			label = "icp";
			memory-region = <&camera_mem>;
		};

		msm_cam_smmu_icp {
			compatible = "qcom,msm-cam-smmu-cb";
			iommus = <&apps_smmu 0x1078 0x2>,
				<&apps_smmu 0x1020 0x8>,
				<&apps_smmu 0x1040 0x8>,
				<&apps_smmu 0x1030 0x0>,
				<&apps_smmu 0x1050 0x0>;
			label = "icp";
			icp_iova_mem_map: iova-mem-map {
				iova-mem-region-firmware {
					iova-region-name = "firmware";
					iova-region-start = <0x0>;
					/*
					 * 4 MiB to match the resized camera_mem coherent
					 * pool (see &camera_mem override above). Legacy was
					 * 5 MiB but the mainline per-device coherent
					 * allocator only serves power-of-two page counts;
					 * 4 MiB > the 1.1 MiB CAMERA_ICP.elf.
					 */
					iova-region-len = <0x400000>;
					iova-region-id = <0x0>;
					status = "ok";
				};

				iova-mem-region-shared {
					iova-region-name = "shared";
					iova-region-start = <0x7400000>;
					iova-region-len = <0x6400000>;
					iova-region-id = <0x1>;
					status = "ok";
				};

				iova-mem-region-secondary-heap {
					iova-region-name = "secheap";
					iova-region-start = <0xd800000>;
					iova-region-len = <0x100000>;
					iova-region-id = <0x4>;
					status = "ok";
				};

				iova-mem-region-io {
					iova-region-name = "io";
					iova-region-start = <0xda00000>;
					iova-region-len = <0xd2500000>;
					iova-region-id = <0x3>;
					status = "ok";
				};

				iova-mem-qdss-region {
					iova-region-name = "qdss";
					iova-region-start = <0xd900000>;
					iova-region-len = <0x100000>;
					iova-region-id = <0x5>;
					qdss-phy-addr = <0x16790000>;
					status = "ok";
				};
			};
		};

		msm_cam_smmu_cpas_cdm {
			compatible = "qcom,msm-cam-smmu-cb";
			iommus = <&apps_smmu 0x1000 0x0>;
			label = "cpas-cdm0";
			cpas_cdm_iova_mem_map: iova-mem-map {
				iova-mem-region-io {
					iova-region-name = "io";
					iova-region-start = <0x7400000>;
					iova-region-len = <0xd8c00000>;
					iova-region-id = <0x3>;
					status = "ok";
				};
			};
		};

		msm_cam_smmu_secure {
			compatible = "qcom,msm-cam-smmu-cb";
			label = "cam-secure";
			qcom,secure-cb;
		};

		msm_cam_smmu_fd {
			compatible = "qcom,msm-cam-smmu-cb";
			iommus = <&apps_smmu 0x1070 0x0>;
			label = "fd";
			fd_iova_mem_map: iova-mem-map {
				iova-mem-region-io {
					iova-region-name = "io";
					iova-region-start = <0x7400000>;
					iova-region-len = <0xd8c00000>;
					iova-region-id = <0x3>;
					status = "ok";
				};
			};
		};
	};

	qcom,cam-cpas@ac40000 {
		cell-index = <0>;
		compatible = "qcom,cam-cpas";
		label = "cpas";
		arch-compat = "cpas_top";
		status = "ok";
		reg-names = "cam_cpas_top", "cam_camnoc";
		reg = <0 0x0ac40000 0 0x1000>,
			<0 0x0ac42000 0 0x5000>;
		reg-cam-base = <0x40000 0x42000>;
		interrupt-names = "cpas_camnoc";
		interrupts = <GIC_SPI 459 IRQ_TYPE_EDGE_RISING>;
		qcom,cpas-hw-ver = <0x170100>; /* Titan v170 v1.0.0 */
		camnoc-axi-min-ib-bw = <3000000000>;
		regulator-names = "camss-vdd";
		camss-vdd-supply = <&titan_top_gdsc>;
		power-domains = <&clock_camcc TITAN_TOP_GDSC>;
		clock-names = "gcc_ahb_clk",
			"gcc_axi_clk",
			"soc_ahb_clk",
			"slow_ahb_clk_src",
			"cpas_ahb_clk",
			"camnoc_axi_clk";
		clocks = <&gcc GCC_CAMERA_AHB_CLK>,
			<&gcc GCC_CAMERA_AXI_CLK>,
			<&clock_camcc CAM_CC_SOC_AHB_CLK>,
			<&clock_camcc CAM_CC_SLOW_AHB_CLK_SRC>,
			<&clock_camcc CAM_CC_CPAS_AHB_CLK>,
			<&clock_camcc CAM_CC_CAMNOC_AXI_CLK>;
		src-clock-name = "slow_ahb_clk_src";
		clock-rates = <0 0 0 0 0 0>,
			<0 0 0 19200000 0 0>,
			<0 0 0 60000000 0 0>,
			<0 0 0 66660000 0 0>,
			<0 0 0 73840000 0 0>,
			<0 0 0 80000000 0 0>,
			<0 0 0 80000000 0 0>;
		clock-cntl-level = "suspend", "minsvs", "lowsvs", "svs",
			"svs_l1", "nominal", "turbo";
		/*
		 * Legacy vdd-corners / vdd-corner-ahb-mapping dropped: those
		 * RPMH_REGULATOR_LEVEL_* corner macros are downstream-only (not
		 * in mainline dt-bindings/regulator/qcom,rpmh-regulator.h), and
		 * the property is OPTIONAL in cam_cpas_soc.c (parsed only when
		 * count>0). They mapped AHB perf levels to rpmh voltage corners
		 * on the old gdsc-as-rpmh-regulator; with the fixed-regulator
		 * gdsc stand-in this is a no-op perf hint, not probe-blocking.
		 */
		client-id-based;
		/*
		 * vamOS: added "csiphy3" (the driver-camera phy on mici, cell_index 3).
		 * The legacy list stopped at csiphy2; csiphy3's CPAS client registration
		 * then fails -EINVAL and aborts its probe (so the 4th cam-csiphy-driver
		 * subdev never appears). Appended with a matching cam_hf_1 axi-port.
		 */
		client-names =
			"csiphy0", "csiphy1", "csiphy2", "csiphy3", "cci0",
			"csid0", "csid1", "csid2",
			"ife0", "ife1", "ife2", "ipe0",
			"ipe1", "cam-cdm-intf0", "cpas-cdm0", "bps0",
			"icp0", "jpeg-dma0", "jpeg-enc0", "fd0", "lrmecpas";
		client-axi-port-names =
			"cam_hf_1", "cam_hf_2", "cam_hf_2", "cam_hf_1", "cam_sf_1",
			"cam_hf_1", "cam_hf_2", "cam_hf_2",
			"cam_hf_1", "cam_hf_2", "cam_hf_2", "cam_sf_1",
			"cam_sf_1", "cam_sf_1", "cam_sf_1", "cam_sf_1",
			"cam_sf_1", "cam_sf_1", "cam_sf_1", "cam_sf_1",
			"cam_sf_1";
		client-bus-camnoc-based;
		qcom,axi-port-list {
			qcom,axi-port1 {
				qcom,axi-port-name = "cam_hf_1";
				qcom,axi-port-mnoc {
					qcom,msm-bus,name = "cam_hf_1_mnoc";
					qcom,msm-bus-vector-dyn-vote;
				};
				qcom,axi-port-camnoc {
					qcom,msm-bus,name = "cam_hf_1_camnoc";
					qcom,msm-bus-vector-dyn-vote;
				};
			};
			qcom,axi-port2 {
				qcom,axi-port-name = "cam_hf_2";
				qcom,axi-port-mnoc {
					qcom,msm-bus,name = "cam_hf_2_mnoc";
					qcom,msm-bus-vector-dyn-vote;
				};
				qcom,axi-port-camnoc {
					qcom,msm-bus,name = "cam_hf_2_camnoc";
					qcom,msm-bus-vector-dyn-vote;
				};
			};
			qcom,axi-port3 {
				qcom,axi-port-name = "cam_sf_1";
				qcom,axi-port-mnoc {
					qcom,msm-bus,name = "cam_sf_1_mnoc";
					qcom,msm-bus-vector-dyn-vote;
				};
				qcom,axi-port-camnoc {
					qcom,msm-bus,name = "cam_sf_1_camnoc";
					qcom,msm-bus-vector-dyn-vote;
				};
			};
		};
	};

	qcom,cam-cdm-intf {
		compatible = "qcom,cam-cdm-intf";
		cell-index = <0>;
		label = "cam-cdm-intf";
		num-hw-cdm = <1>;
		cdm-client-names = "vfe",
			"jpegdma",
			"jpegenc",
			"fd",
			"lrmecdm";
		status = "ok";
	};

	qcom,cpas-cdm0@ac48000 {
		cell-index = <0>;
		compatible = "qcom,cam170-cpas-cdm0";
		label = "cpas-cdm";
		reg = <0 0x0ac48000 0 0x1000>;
		reg-names = "cpas-cdm";
		reg-cam-base = <0x48000>;
		interrupts = <GIC_SPI 461 IRQ_TYPE_EDGE_RISING>;
		interrupt-names = "cpas-cdm";
		regulator-names = "camss";
		camss-supply = <&titan_top_gdsc>;
		clock-names = "gcc_camera_ahb",
			"gcc_camera_axi",
			"cam_cc_soc_ahb_clk",
			"cam_cc_cpas_ahb_clk",
			"cam_cc_camnoc_axi_clk";
		clocks = <&gcc GCC_CAMERA_AHB_CLK>,
			<&gcc GCC_CAMERA_AXI_CLK>,
			<&clock_camcc CAM_CC_SOC_AHB_CLK>,
			<&clock_camcc CAM_CC_CPAS_AHB_CLK>,
			<&clock_camcc CAM_CC_CAMNOC_AXI_CLK>;
		clock-rates = <0 0 0 0 0>;
		clock-cntl-level = "svs";
		cdm-client-names = "ife";
		status = "ok";
	};

	qcom,cam-isp {
		compatible = "qcom,cam-isp";
		arch-compat = "ife";
		status = "ok";
	};

	cam_csid0: qcom,csid0@acb3000 {
		cell-index = <0>;
		compatible = "qcom,csid170";
		reg-names = "csid";
		reg = <0 0x0acb3000 0 0x1000>;
		reg-cam-base = <0xb3000>;
		interrupt-names = "csid";
		interrupts = <GIC_SPI 464 IRQ_TYPE_EDGE_RISING>;
		regulator-names = "camss", "ife0";
		camss-supply = <&titan_top_gdsc>;
		ife0-supply = <&ife_0_gdsc>;
		/* vamOS: attach real IFE_0 GDSC genpd (see vfe0 note). */
		power-domains = <&clock_camcc IFE_0_GDSC>;
		clock-names = "camera_ahb",
			"camera_axi",
			"soc_ahb_clk",
			"cpas_ahb_clk",
			"slow_ahb_clk_src",
			"ife_csid_clk",
			"ife_csid_clk_src",
			"ife_cphy_rx_clk",
			"cphy_rx_clk_src",
			"ife_clk",
			"ife_clk_src",
			"camnoc_axi_clk",
			"ife_axi_clk";
		clocks = <&gcc GCC_CAMERA_AHB_CLK>,
			<&gcc GCC_CAMERA_AXI_CLK>,
			<&clock_camcc CAM_CC_SOC_AHB_CLK>,
			<&clock_camcc CAM_CC_CPAS_AHB_CLK>,
			<&clock_camcc CAM_CC_SLOW_AHB_CLK_SRC>,
			<&clock_camcc CAM_CC_IFE_0_CSID_CLK>,
			<&clock_camcc CAM_CC_IFE_0_CSID_CLK_SRC>,
			<&clock_camcc CAM_CC_IFE_0_CPHY_RX_CLK>,
			<&clock_camcc CAM_CC_CPHY_RX_CLK_SRC>,
			<&clock_camcc CAM_CC_IFE_0_CLK>,
			<&clock_camcc CAM_CC_IFE_0_CLK_SRC>,
			<&clock_camcc CAM_CC_CAMNOC_AXI_CLK>,
			<&clock_camcc CAM_CC_IFE_0_AXI_CLK>;
		clock-rates =
			<0 0 0 0 0 0 384000000 0 0 0 404000000 0 0>,
			<0 0 0 0 0 0 538000000 0 0 0 600000000 0 0>;
		clock-cntl-level = "svs", "turbo";
		src-clock-name = "ife_csid_clk_src";
		clock-control-debugfs = "true";
		status = "ok";
	};

	cam_vfe0: qcom,vfe0@acaf000 {
		cell-index = <0>;
		compatible = "qcom,vfe170";
		reg-names = "ife";
		reg = <0 0x0acaf000 0 0x4000>;
		reg-cam-base = <0xaf000>;
		interrupt-names = "ife";
		interrupts = <GIC_SPI 465 IRQ_TYPE_EDGE_RISING>;
		regulator-names = "camss", "ife0";
		camss-supply = <&titan_top_gdsc>;
		ife0-supply = <&ife_0_gdsc>;
		/*
		 * vamOS: the camss/ife0 "supplies" above are fake always-on fixed
		 * regulators (the driver calls regulator_enable on them). The REAL
		 * GDSCs live in &clock_camcc as genpd power-domains; attach IFE_0_GDSC
		 * (a subdomain of TITAN_TOP_GDSC, which genpd powers up as the parent)
		 * so the IFE_0 power rail is actually on — otherwise clk_enable(ife_clk)
		 * returns -EBUSY (power domain off) and VFE soc-enable fails.
		 */
		power-domains = <&clock_camcc IFE_0_GDSC>;
		clock-names = "camera_ahb",
			"camera_axi",
			"soc_ahb_clk",
			"cpas_ahb_clk",
			"slow_ahb_clk_src",
			"ife_clk",
			"ife_clk_src",
			"camnoc_axi_clk",
			"ife_axi_clk";
		clocks = <&gcc GCC_CAMERA_AHB_CLK>,
			<&gcc GCC_CAMERA_AXI_CLK>,
			<&clock_camcc CAM_CC_SOC_AHB_CLK>,
			<&clock_camcc CAM_CC_CPAS_AHB_CLK>,
			<&clock_camcc CAM_CC_SLOW_AHB_CLK_SRC>,
			<&clock_camcc CAM_CC_IFE_0_CLK>,
			<&clock_camcc CAM_CC_IFE_0_CLK_SRC>,
			<&clock_camcc CAM_CC_CAMNOC_AXI_CLK>,
			<&clock_camcc CAM_CC_IFE_0_AXI_CLK>;
		clock-rates =
			<0 0 0 0 0 0 404000000 0 0>,
			<0 0 0 0 0 0 480000000 0 0>,
			<0 0 0 0 0 0 600000000 0 0>;
		clock-cntl-level = "svs", "svs_l1", "turbo";
		src-clock-name = "ife_clk_src";
		clock-control-debugfs = "true";
		clock-names-option = "ife_dsp_clk";
		clocks-option = <&clock_camcc CAM_CC_IFE_0_DSP_CLK>;
		clock-rates-option = <600000000>;
		status = "ok";
	};

	cam_csid1: qcom,csid1@acba000 {
		cell-index = <1>;
		compatible = "qcom,csid170";
		reg-names = "csid";
		reg = <0 0x0acba000 0 0x1000>;
		reg-cam-base = <0xba000>;
		interrupt-names = "csid";
		interrupts = <GIC_SPI 466 IRQ_TYPE_EDGE_RISING>;
		regulator-names = "camss", "ife1";
		camss-supply = <&titan_top_gdsc>;
		ife1-supply = <&ife_1_gdsc>;
		/* vamOS: attach real IFE_1 GDSC genpd (see vfe0 note). */
		power-domains = <&clock_camcc IFE_1_GDSC>;
		clock-names = "camera_ahb",
			"camera_axi",
			"soc_ahb_clk",
			"cpas_ahb_clk",
			"slow_ahb_clk_src",
			"ife_csid_clk",
			"ife_csid_clk_src",
			"ife_cphy_rx_clk",
			"cphy_rx_clk_src",
			"ife_clk",
			"ife_clk_src",
			"camnoc_axi_clk",
			"ife_axi_clk";
		clocks = <&gcc GCC_CAMERA_AHB_CLK>,
			<&gcc GCC_CAMERA_AXI_CLK>,
			<&clock_camcc CAM_CC_SOC_AHB_CLK>,
			<&clock_camcc CAM_CC_CPAS_AHB_CLK>,
			<&clock_camcc CAM_CC_SLOW_AHB_CLK_SRC>,
			<&clock_camcc CAM_CC_IFE_1_CSID_CLK>,
			<&clock_camcc CAM_CC_IFE_1_CSID_CLK_SRC>,
			<&clock_camcc CAM_CC_IFE_1_CPHY_RX_CLK>,
			<&clock_camcc CAM_CC_CPHY_RX_CLK_SRC>,
			<&clock_camcc CAM_CC_IFE_1_CLK>,
			<&clock_camcc CAM_CC_IFE_1_CLK_SRC>,
			<&clock_camcc CAM_CC_CAMNOC_AXI_CLK>,
			<&clock_camcc CAM_CC_IFE_1_AXI_CLK>;
		clock-rates =
			<0 0 0 0 0 0 384000000 0 0 0 404000000 0 0>,
			<0 0 0 0 0 0 538000000 0 0 0 600000000 0 0>;
		clock-cntl-level = "svs", "turbo";
		src-clock-name = "ife_csid_clk_src";
		clock-control-debugfs = "true";
		status = "ok";
	};

	cam_vfe1: qcom,vfe1@acb6000 {
		cell-index = <1>;
		compatible = "qcom,vfe170";
		reg-names = "ife";
		reg = <0 0x0acb6000 0 0x4000>;
		reg-cam-base = <0xb6000>;
		interrupt-names = "ife";
		interrupts = <GIC_SPI 467 IRQ_TYPE_EDGE_RISING>;
		regulator-names = "camss", "ife1";
		camss-supply = <&titan_top_gdsc>;
		ife1-supply = <&ife_1_gdsc>;
		/* vamOS: attach real IFE_1 GDSC genpd (see vfe0 note). */
		power-domains = <&clock_camcc IFE_1_GDSC>;
		clock-names = "camera_ahb",
			"camera_axi",
			"soc_ahb_clk",
			"cpas_ahb_clk",
			"slow_ahb_clk_src",
			"ife_clk",
			"ife_clk_src",
			"camnoc_axi_clk",
			"ife_axi_clk";
		clocks = <&gcc GCC_CAMERA_AHB_CLK>,
			<&gcc GCC_CAMERA_AXI_CLK>,
			<&clock_camcc CAM_CC_SOC_AHB_CLK>,
			<&clock_camcc CAM_CC_CPAS_AHB_CLK>,
			<&clock_camcc CAM_CC_SLOW_AHB_CLK_SRC>,
			<&clock_camcc CAM_CC_IFE_1_CLK>,
			<&clock_camcc CAM_CC_IFE_1_CLK_SRC>,
			<&clock_camcc CAM_CC_CAMNOC_AXI_CLK>,
			<&clock_camcc CAM_CC_IFE_1_AXI_CLK>;
		clock-rates =
			<0 0 0 0 0 0 404000000 0 0>,
			<0 0 0 0 0 0 480000000 0 0>,
			<0 0 0 0 0 0 600000000 0 0>;
		clock-cntl-level = "svs", "svs_l1", "turbo";
		src-clock-name = "ife_clk_src";
		clock-control-debugfs = "true";
		clock-names-option = "ife_dsp_clk";
		clocks-option = <&clock_camcc CAM_CC_IFE_1_DSP_CLK>;
		clock-rates-option = <600000000>;
		status = "ok";
	};

	cam_csid_lite: qcom,csid-lite@acc8000 {
		cell-index = <2>;
		compatible = "qcom,csid-lite170";
		reg-names = "csid-lite";
		reg = <0 0x0acc8000 0 0x1000>;
		reg-cam-base = <0xc8000>;
		interrupt-names = "csid-lite";
		interrupts = <GIC_SPI 468 IRQ_TYPE_EDGE_RISING>;
		regulator-names = "camss";
		camss-supply = <&titan_top_gdsc>;
		/* vamOS: attach real TITAN_TOP GDSC genpd (see vfe0 note). */
		power-domains = <&clock_camcc TITAN_TOP_GDSC>;
		clock-names = "camera_ahb",
			"camera_axi",
			"soc_ahb_clk",
			"cpas_ahb_clk",
			"slow_ahb_clk_src",
			"ife_csid_clk",
			"ife_csid_clk_src",
			"ife_cphy_rx_clk",
			"cphy_rx_clk_src",
			"ife_clk",
			"ife_clk_src",
			"camnoc_axi_clk";
		clocks = <&gcc GCC_CAMERA_AHB_CLK>,
			<&gcc GCC_CAMERA_AXI_CLK>,
			<&clock_camcc CAM_CC_SOC_AHB_CLK>,
			<&clock_camcc CAM_CC_CPAS_AHB_CLK>,
			<&clock_camcc CAM_CC_SLOW_AHB_CLK_SRC>,
			<&clock_camcc CAM_CC_IFE_LITE_CSID_CLK>,
			<&clock_camcc CAM_CC_IFE_LITE_CSID_CLK_SRC>,
			<&clock_camcc CAM_CC_IFE_LITE_CPHY_RX_CLK>,
			<&clock_camcc CAM_CC_CPHY_RX_CLK_SRC>,
			<&clock_camcc CAM_CC_IFE_LITE_CLK>,
			<&clock_camcc CAM_CC_IFE_LITE_CLK_SRC>,
			<&clock_camcc CAM_CC_CAMNOC_AXI_CLK>;
		clock-rates =
			<0 0 0 0 0 0 384000000 0 0 0 404000000 0>,
			<0 0 0 0 0 0 538000000 0 0 0 600000000 0>;
		clock-cntl-level = "svs", "turbo";
		src-clock-name = "ife_csid_clk_src";
		clock-control-debugfs = "true";
		status = "ok";
	};

	cam_vfe_lite: qcom,vfe-lite@acc4000 {
		cell-index = <2>;
		compatible = "qcom,vfe-lite170";
		reg-names = "ife-lite";
		reg = <0 0x0acc4000 0 0x4000>;
		reg-cam-base = <0xc4000>;
		interrupt-names = "ife-lite";
		interrupts = <GIC_SPI 469 IRQ_TYPE_EDGE_RISING>;
		regulator-names = "camss";
		camss-supply = <&titan_top_gdsc>;
		/* vamOS: attach real TITAN_TOP GDSC genpd (see vfe0 note). */
		power-domains = <&clock_camcc TITAN_TOP_GDSC>;
		clock-names = "camera_ahb",
			"camera_axi",
			"soc_ahb_clk",
			"cpas_ahb_clk",
			"slow_ahb_clk_src",
			"ife_clk",
			"ife_clk_src",
			"camnoc_axi_clk";
		clocks = <&gcc GCC_CAMERA_AHB_CLK>,
			<&gcc GCC_CAMERA_AXI_CLK>,
			<&clock_camcc CAM_CC_SOC_AHB_CLK>,
			<&clock_camcc CAM_CC_CPAS_AHB_CLK>,
			<&clock_camcc CAM_CC_SLOW_AHB_CLK_SRC>,
			<&clock_camcc CAM_CC_IFE_LITE_CLK>,
			<&clock_camcc CAM_CC_IFE_LITE_CLK_SRC>,
			<&clock_camcc CAM_CC_CAMNOC_AXI_CLK>;
		clock-rates =
			<0 0 0 0 0 0 404000000 0>,
			<0 0 0 0 0 0 480000000 0>,
			<0 0 0 0 0 0 600000000 0>;
		clock-cntl-level = "svs", "svs_l1", "turbo";
		src-clock-name = "ife_clk_src";
		clock-control-debugfs = "true";
		status = "ok";
	};

	qcom,cam-icp {
		compatible = "qcom,cam-icp";
		compat-hw-name = "qcom,a5",
			"qcom,ipe0",
			"qcom,ipe1",
			"qcom,bps";
		num-a5 = <1>;
		num-ipe = <2>;
		num-bps = <1>;
		status = "ok";
	};

	cam_a5: qcom,a5@ac00000 {
		cell-index = <0>;
		compatible = "qcom,cam-a5";
		reg = <0 0x0ac00000 0 0x6000>,
			<0 0x0ac10000 0 0x8000>,
			<0 0x0ac18000 0 0x3000>;
		reg-names = "a5_qgic", "a5_sierra", "a5_csr";
		reg-cam-base = <0x00000 0x10000 0x18000>;
		interrupts = <GIC_SPI 463 IRQ_TYPE_EDGE_RISING>;
		interrupt-names = "a5";
		regulator-names = "camss-vdd";
		camss-vdd-supply = <&titan_top_gdsc>;
		clock-names = "gcc_cam_ahb_clk",
			"gcc_cam_axi_clk",
			"soc_fast_ahb",
			"soc_ahb_clk",
			"cpas_ahb_clk",
			"camnoc_axi_clk",
			"icp_clk",
			"icp_clk_src";
		clocks = <&gcc GCC_CAMERA_AHB_CLK>,
				<&gcc GCC_CAMERA_AXI_CLK>,
				<&clock_camcc CAM_CC_FAST_AHB_CLK_SRC>,
				<&clock_camcc CAM_CC_SOC_AHB_CLK>,
				<&clock_camcc CAM_CC_CPAS_AHB_CLK>,
				<&clock_camcc CAM_CC_CAMNOC_AXI_CLK>,
				<&clock_camcc CAM_CC_ICP_CLK>,
				<&clock_camcc CAM_CC_ICP_CLK_SRC>;
		clock-rates =
			<0 0 200000000 0 0 0 0 400000000>,
			<0 0 200000000 0 0 0 0 600000000>;
		clock-cntl-level = "svs", "turbo";
		fw_name = "CAMERA_ICP.elf";
		ubwc-cfg = <0x7B 0x1EF>;
		status = "ok";
	};

	cam_ipe0: qcom,ipe0 {
		cell-index = <0>;
		compatible = "qcom,cam-ipe";
		reg = <0 0x0ac87000 0 0x3000>;
		reg-names = "ipe0_top";
		reg-cam-base = <0x87000>;
		regulator-names = "ipe0-vdd";
		ipe0-vdd-supply = <&ipe_0_gdsc>;
		/*
		 * vamOS: attach the real IPE_0 GDSC genpd so the camcc IPE_0
		 * power domain is actually on before ipe_0_*_clk enable. The
		 * fixed-regulator stand-in above only satisfies regulator_get();
		 * without this genpd attach the GDSC stays off and clk enable
		 * returns -EBUSY (single-domain auto-attach via dev_pm_domain_attach).
		 */
		power-domains = <&clock_camcc IPE_0_GDSC>;
		clock-names = "ipe_0_ahb_clk",
			"ipe_0_areg_clk",
			"ipe_0_axi_clk",
			"ipe_0_clk",
			"ipe_0_clk_src";
		src-clock-name = "ipe_0_clk_src";
		clock-control-debugfs = "true";
		clocks = <&clock_camcc CAM_CC_IPE_0_AHB_CLK>,
				<&clock_camcc CAM_CC_IPE_0_AREG_CLK>,
				<&clock_camcc CAM_CC_IPE_0_AXI_CLK>,
				<&clock_camcc CAM_CC_IPE_0_CLK>,
				<&clock_camcc CAM_CC_IPE_0_CLK_SRC>;
		clock-rates =
			<0 0 0 0 404000000>,
			<0 0 0 0 480000000>,
			<0 0 0 0 538000000>,
			<0 0 0 0 600000000>;
		clock-cntl-level = "svs",
			"svs_l1", "nominal", "turbo";
		status = "ok";
	};

	cam_ipe1: qcom,ipe1 {
		cell-index = <1>;
		compatible = "qcom,cam-ipe";
		reg = <0 0x0ac91000 0 0x3000>;
		reg-names = "ipe1_top";
		reg-cam-base = <0x91000>;
		regulator-names = "ipe1-vdd";
		ipe1-vdd-supply = <&ipe_1_gdsc>;
		/* vamOS: attach real IPE_1 GDSC genpd (see ipe0 note). */
		power-domains = <&clock_camcc IPE_1_GDSC>;
		clock-names = "ipe_1_ahb_clk",
			"ipe_1_areg_clk",
			"ipe_1_axi_clk",
			"ipe_1_clk",
			"ipe_1_clk_src";
		src-clock-name = "ipe_1_clk_src";
		clock-control-debugfs = "true";
		clocks = <&clock_camcc CAM_CC_IPE_1_AHB_CLK>,
				<&clock_camcc CAM_CC_IPE_1_AREG_CLK>,
				<&clock_camcc CAM_CC_IPE_1_AXI_CLK>,
				<&clock_camcc CAM_CC_IPE_1_CLK>,
				<&clock_camcc CAM_CC_IPE_1_CLK_SRC>;
		clock-rates =
			<0 0 0 0 404000000>,
			<0 0 0 0 480000000>,
			<0 0 0 0 538000000>,
			<0 0 0 0 600000000>;
		clock-cntl-level = "svs",
			"svs_l1", "nominal", "turbo";
		status = "ok";
	};

	cam_bps: qcom,bps {
		cell-index = <0>;
		compatible = "qcom,cam-bps";
		reg = <0 0x0ac6f000 0 0x3000>;
		reg-names = "bps_top";
		reg-cam-base = <0x6f000>;
		regulator-names = "bps-vdd";
		bps-vdd-supply = <&bps_gdsc>;
		/* vamOS: attach real BPS GDSC genpd (see ipe0 note). */
		power-domains = <&clock_camcc BPS_GDSC>;
		clock-names = "bps_ahb_clk",
			"bps_areg_clk",
			"bps_axi_clk",
			"bps_clk",
			"bps_clk_src";
		src-clock-name = "bps_clk_src";
		clock-control-debugfs = "true";
		clocks = <&clock_camcc CAM_CC_BPS_AHB_CLK>,
				<&clock_camcc CAM_CC_BPS_AREG_CLK>,
				<&clock_camcc CAM_CC_BPS_AXI_CLK>,
				<&clock_camcc CAM_CC_BPS_CLK>,
				<&clock_camcc CAM_CC_BPS_CLK_SRC>;
		clock-rates =
			<0 0 0 0 404000000>,
			<0 0 0 0 480000000>,
			<0 0 0 0 600000000>,
			<0 0 0 0 600000000>;
		clock-cntl-level = "svs",
			"svs_l1", "nominal", "turbo";
		status = "ok";
	};

	qcom,cam-jpeg {
		compatible = "qcom,cam-jpeg";
		compat-hw-name = "qcom,jpegenc",
			"qcom,jpegdma";
		num-jpeg-enc = <1>;
		num-jpeg-dma = <1>;
		status = "ok";
	};

	cam_jpeg_enc: qcom,jpegenc@ac4e000 {
		cell-index = <0>;
		compatible = "qcom,cam_jpeg_enc";
		reg-names = "jpege_hw";
		reg = <0 0x0ac4e000 0 0x4000>;
		reg-cam-base = <0x4e000>;
		interrupt-names = "jpeg";
		interrupts = <GIC_SPI 474 IRQ_TYPE_EDGE_RISING>;
		regulator-names = "camss-vdd";
		camss-vdd-supply = <&titan_top_gdsc>;
		clock-names = "camera_ahb",
			"camera_axi",
			"soc_ahb_clk",
			"cpas_ahb_clk",
			"camnoc_axi_clk",
			"jpegenc_clk_src",
			"jpegenc_clk";
		clocks = <&gcc GCC_CAMERA_AHB_CLK>,
			<&gcc GCC_CAMERA_AXI_CLK>,
			<&clock_camcc CAM_CC_SOC_AHB_CLK>,
			<&clock_camcc CAM_CC_CPAS_AHB_CLK>,
			<&clock_camcc CAM_CC_CAMNOC_AXI_CLK>,
			<&clock_camcc CAM_CC_JPEG_CLK_SRC>,
			<&clock_camcc CAM_CC_JPEG_CLK>;
		clock-rates = <0 0 0 0 0 600000000 0>;
		src-clock-name = "jpegenc_clk_src";
		clock-cntl-level = "nominal";
		status = "ok";
	};

	cam_jpeg_dma: qcom,jpegdma@ac52000 {
		cell-index = <0>;
		compatible = "qcom,cam_jpeg_dma";
		reg-names = "jpegdma_hw";
		reg = <0 0x0ac52000 0 0x4000>;
		reg-cam-base = <0x52000>;
		interrupt-names = "jpegdma";
		interrupts = <GIC_SPI 475 IRQ_TYPE_EDGE_RISING>;
		regulator-names = "camss-vdd";
		camss-vdd-supply = <&titan_top_gdsc>;
		clock-names = "camera_ahb",
			"camera_axi",
			"soc_ahb_clk",
			"cpas_ahb_clk",
			"camnoc_axi_clk",
			"jpegdma_clk_src",
			"jpegdma_clk";
		clocks = <&gcc GCC_CAMERA_AHB_CLK>,
			<&gcc GCC_CAMERA_AXI_CLK>,
			<&clock_camcc CAM_CC_SOC_AHB_CLK>,
			<&clock_camcc CAM_CC_CPAS_AHB_CLK>,
			<&clock_camcc CAM_CC_CAMNOC_AXI_CLK>,
			<&clock_camcc CAM_CC_JPEG_CLK_SRC>,
			<&clock_camcc CAM_CC_JPEG_CLK>;
		clock-rates = <0 0 0 0 0 600000000 0>;
		src-clock-name = "jpegdma_clk_src";
		clock-cntl-level = "nominal";
		status = "ok";
	};

	qcom,cam-fd {
		compatible = "qcom,cam-fd";
		compat-hw-name = "qcom,fd";
		num-fd = <1>;
		status = "ok";
	};

	cam_fd: qcom,fd@ac5a000 {
		cell-index = <0>;
		compatible = "qcom,fd41";
		reg-names = "fd_core", "fd_wrapper";
		reg = <0 0x0ac5a000 0 0x1000>,
			<0 0x0ac5b000 0 0x400>;
		reg-cam-base = <0x5a000 0x5b000>;
		interrupt-names = "fd";
		interrupts = <GIC_SPI 462 IRQ_TYPE_EDGE_RISING>;
		regulator-names = "camss-vdd";
		camss-vdd-supply = <&titan_top_gdsc>;
		clock-names = "gcc_ahb_clk",
			"gcc_axi_clk",
			"soc_ahb_clk",
			"cpas_ahb_clk",
			"camnoc_axi_clk",
			"fd_core_clk_src",
			"fd_core_clk",
			"fd_core_uar_clk";
		clocks = <&gcc GCC_CAMERA_AHB_CLK>,
			<&gcc GCC_CAMERA_AXI_CLK>,
			<&clock_camcc CAM_CC_SOC_AHB_CLK>,
			<&clock_camcc CAM_CC_CPAS_AHB_CLK>,
			<&clock_camcc CAM_CC_CAMNOC_AXI_CLK>,
			<&clock_camcc CAM_CC_FD_CORE_CLK_SRC>,
			<&clock_camcc CAM_CC_FD_CORE_CLK>,
			<&clock_camcc CAM_CC_FD_CORE_UAR_CLK>;
		src-clock-name = "fd_core_clk_src";
		clock-control-debugfs = "true";
		clock-cntl-level = "svs", "svs_l1", "turbo";
		clock-rates =
			<0 0 0 0 0 400000000 0 0>,
			<0 0 0 0 0 538000000 0 0>,
			<0 0 0 0 0 600000000 0 0>;
		status = "ok";
	};
};

/* ------------------------------------------------------------------------
 * Camera sensors (ported from legacy sdm845-camera-sensor-mtp.dtsi).
 * 4x qcom,cam-sensor on cam_cci; phy/cci-master = (0,0)(1,0)(2,1)(3,1);
 * roll 180/180/180/270. DT does not name the part — camerad probes the
 * chip-id (0x5304 family) over CCI. Supplies mapped onto vamOS rails:
 *   cam_vio  &pm8998_lvs1  -> &vreg_lvs1a_1p8
 *   cam_vana &pmi8998_bob  -> &vreg_bob          (sensors 0-2)
 *   cam_vana &camera_vana_ldo (sensor 3, kept)
 *   cam_vdig &camera_rear_ldo (sensors 0-2, kept)
 *   cam_vdig &camera_ldo      (sensor 3, kept)
 *   cam_clk  &titan_top_gdsc  (fixed stand-in)
 * mclk pinctrl drive-strength reductions are board-specific -> mici.dts.
 * ------------------------------------------------------------------------ */
&cam_cci {
	qcom,cam-res-mgr {
		compatible = "qcom,cam-res-mgr";
		status = "ok";
		/*
		 * Shared VANA pin (TLMM gpio8), used by cam-sensor@0 AND @1.
		 * cam_res_mgr matches requested gpios against this list to
		 * refcount a shared pin instead of failing the 2nd request
		 * -EBUSY. On 6.18 of_get_named_gpio() returns the GLOBAL gpio
		 * number (TLMM base 552 + 8 = 560), so the match list must use
		 * the global number too — the legacy raw "<8>" never matched and
		 * the 2nd sensor's VANA request failed -EBUSY, aborting power-up.
		 */
		shared-gpios = <560>;
		pinctrl-names = "cam_res_mgr_default", "cam_res_mgr_suspend";
		pinctrl-0 = <&cam_res_mgr_active>;
		pinctrl-1 = <&cam_res_mgr_suspend>;
	};

	qcom,cam-sensor@0 {
		cell-index = <0>;
		compatible = "qcom,cam-sensor";
		reg = <0x0>;
		csiphy-sd-index = <0>;
		sensor-position-roll = <180>;
		sensor-position-pitch = <0>;
		sensor-position-yaw = <0>;
		cam_vio-supply = <&vreg_lvs1a_1p8>;
		cam_vana-supply = <&vreg_bob>;
		cam_vdig-supply = <&camera_rear_ldo>;
		cam_clk-supply = <&titan_top_gdsc>;
		regulator-names = "cam_vio", "cam_vana", "cam_vdig", "cam_clk";
		rgltr-cntrl-support;
		rgltr-min-voltage = <0 3312000 1050000 0>;
		rgltr-max-voltage = <0 3600000 1050000 0>;
		rgltr-load-current = <0 80000 105000 0>;
		gpio-no-mux = <0>;
		pinctrl-names = "cam_default", "cam_suspend";
		/*
		 * Only mclk is pinmuxed (cam_mclk function). The reset/vana pins
		 * are driven via gpio_request + gpio_set_value by the sensor
		 * power-sequencer, so they must NOT also be claimed here as a
		 * "gpio" pinmux function — that double-claim made the reset
		 * gpio_request fail -EBUSY. (Dropped &cam_sensor_rear_active.)
		 */
		pinctrl-0 = <&cam_sensor_mclk0_active>;
		pinctrl-1 = <&cam_sensor_mclk0_suspend>;
		gpios = <&tlmm 13 0>,
			<&tlmm 9 0>,
			<&tlmm 8 0>;
		gpio-reset = <1>;
		gpio-vana = <2>;
		gpio-req-tbl-num = <0 1 2>;
		gpio-req-tbl-flags = <1 0 0>;
		gpio-req-tbl-label = "CAMIF_MCLK0", "CAM_RESET0", "CAM_VANA0";
		sensor-mode = <0>;
		cci-master = <0>;
		status = "ok";
		clocks = <&clock_camcc CAM_CC_MCLK0_CLK>;
		clock-names = "cam_clk";
		clock-cntl-level = "turbo";
		clock-rates = <24000000>;
	};

	qcom,cam-sensor@1 {
		cell-index = <1>;
		compatible = "qcom,cam-sensor";
		reg = <0x1>;
		csiphy-sd-index = <1>;
		sensor-position-roll = <180>;
		sensor-position-pitch = <0>;
		sensor-position-yaw = <0>;
		cam_vio-supply = <&vreg_lvs1a_1p8>;
		cam_vana-supply = <&vreg_bob>;
		cam_vdig-supply = <&camera_rear_ldo>;
		cam_clk-supply = <&titan_top_gdsc>;
		regulator-names = "cam_vio", "cam_vana", "cam_vdig", "cam_clk";
		rgltr-cntrl-support;
		rgltr-min-voltage = <0 3312000 1050000 0>;
		rgltr-max-voltage = <0 3600000 1050000 0>;
		rgltr-load-current = <0 80000 105000 0>;
		gpio-no-mux = <0>;
		pinctrl-names = "cam_default", "cam_suspend";
		pinctrl-0 = <&cam_sensor_mclk1_active>;
		pinctrl-1 = <&cam_sensor_mclk1_suspend>;
		gpios = <&tlmm 14 0>,
			<&tlmm 7 0>,
			<&tlmm 8 0>;
		gpio-reset = <1>;
		gpio-vana = <2>;
		gpio-req-tbl-num = <0 1 2>;
		gpio-req-tbl-flags = <1 0 0>;
		gpio-req-tbl-label = "CAMIF_MCLK1", "CAM_RESET1", "CAM_VANA1";
		sensor-mode = <0>;
		cci-master = <0>;
		status = "ok";
		clocks = <&clock_camcc CAM_CC_MCLK1_CLK>;
		clock-names = "cam_clk";
		clock-cntl-level = "turbo";
		clock-rates = <24000000>;
	};

	qcom,cam-sensor@2 {
		cell-index = <2>;
		compatible = "qcom,cam-sensor";
		reg = <0x02>;
		csiphy-sd-index = <2>;
		sensor-position-roll = <180>;
		sensor-position-pitch = <0>;
		sensor-position-yaw = <0>;
		cam_vio-supply = <&vreg_lvs1a_1p8>;
		cam_vana-supply = <&vreg_bob>;
		cam_vdig-supply = <&camera_rear_ldo>;
		cam_clk-supply = <&titan_top_gdsc>;
		regulator-names = "cam_vio", "cam_vana", "cam_vdig", "cam_clk";
		rgltr-cntrl-support;
		rgltr-min-voltage = <0 3312000 1050000 0>;
		rgltr-max-voltage = <0 3600000 1050000 0>;
		rgltr-load-current = <0 80000 105000 0>;
		gpio-no-mux = <0>;
		pinctrl-names = "cam_default", "cam_suspend";
		pinctrl-0 = <&cam_sensor_mclk2_active>;
		pinctrl-1 = <&cam_sensor_mclk2_suspend>;
		gpios = <&tlmm 15 0>,
			<&tlmm 12 0>,
			<&tlmm 8 0>;
		gpio-reset = <1>;
		gpio-vana = <2>;
		gpio-req-tbl-num = <0 1 2>;
		gpio-req-tbl-flags = <1 0 0>;
		gpio-req-tbl-label = "CAMIF_MCLK2", "CAM_RESET2", "CAM_VANA2";
		sensor-mode = <0>;
		cci-master = <1>;
		status = "ok";
		clocks = <&clock_camcc CAM_CC_MCLK2_CLK>;
		clock-names = "cam_clk";
		clock-cntl-level = "turbo";
		clock-rates = <24000000>;
	};

	qcom,cam-sensor@3 {
		cell-index = <3>;
		compatible = "qcom,cam-sensor";
		reg = <0x03>;
		csiphy-sd-index = <3>;
		sensor-position-roll = <270>;
		sensor-position-pitch = <0>;
		sensor-position-yaw = <0>;
		cam_vio-supply = <&vreg_lvs1a_1p8>;
		cam_vana-supply = <&camera_vana_ldo>;
		cam_vdig-supply = <&camera_ldo>;
		cam_clk-supply = <&titan_top_gdsc>;
		regulator-names = "cam_vio", "cam_vana", "cam_vdig", "cam_clk";
		rgltr-cntrl-support;
		rgltr-min-voltage = <0 2850000 1050000 0>;
		rgltr-max-voltage = <0 2850000 1050000 0>;
		rgltr-load-current = <0 80000 105000 0>;
		gpio-no-mux = <0>;
		pinctrl-names = "cam_default", "cam_suspend";
		pinctrl-0 = <&cam_sensor_mclk3_active>;
		pinctrl-1 = <&cam_sensor_mclk3_suspend>;
		gpios = <&tlmm 16 0>,
			<&tlmm 9 0>;
		gpio-reset = <1>;
		gpio-req-tbl-num = <0 1>;
		gpio-req-tbl-flags = <1 0>;
		gpio-req-tbl-label = "CAMIF_MCLK3", "CAM_RESET3";
		sensor-mode = <0>;
		cci-master = <1>;
		status = "ok";
		clocks = <&clock_camcc CAM_CC_MCLK3_CLK>;
		clock-names = "cam_clk";
		clock-cntl-level = "turbo";
		clock-rates = <24000000>;
	};
};
